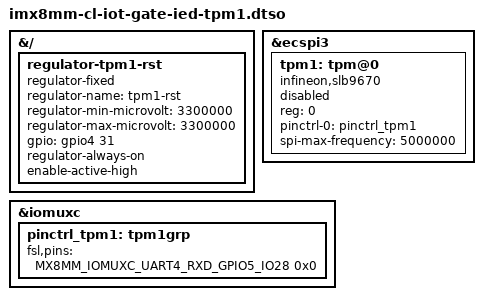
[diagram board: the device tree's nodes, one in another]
// SPDX-License-Identifier: (GPL-2.0+ OR MIT)
/*
 * Copyright 2021 Linaro
 */

/dts-v1/;
/plugin/;

#include <dt-bindings/gpio/gpio.h>

#include "imx8mm-pinfunc.h"

&{/} {
	regulator-tpm1-rst {
		compatible = "regulator-fixed";
		regulator-name = "tpm1-rst";
		regulator-min-microvolt = <3300000>;
		regulator-max-microvolt = <3300000>;
		gpio = <&gpio4 31 GPIO_ACTIVE_HIGH>;
		regulator-always-on;
		enable-active-high;
	};
};

&ecspi3 {
	#address-cells = <1>;
	#size-cells = <0>;

	tpm1: tpm@0 {
		compatible = "infineon,slb9670", "tcg,tpm_tis-spi";
		reg = <0>;
		pinctrl-names = "default";
		pinctrl-0 = <&pinctrl_tpm1>;
		spi-max-frequency = <5000000>;
		status = "disabled";
	};
};

&iomuxc {
	pinctrl_tpm1: tpm1grp {
		fsl,pins = <
			MX8MM_IOMUXC_UART4_RXD_GPIO5_IO28	0x0
		>;
	};
};
